# STM32L4Q5ZGT6P register map
File version: 1.0
Registers are 32-bit, access not given, reset 0x0 unless marked. A register's access mark holds for its fields unless they carry their own. Offsets are from the block's base; [hi:lo] are bit positions; {n}, {i} and the like mark numbered series; 'fields as' and 'values as' point back to an identical list.

## OPAMP
Base 0x40007800
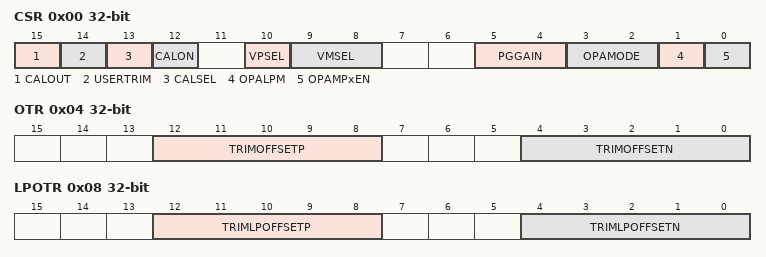
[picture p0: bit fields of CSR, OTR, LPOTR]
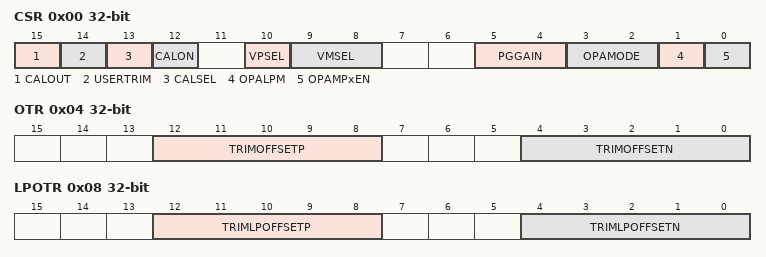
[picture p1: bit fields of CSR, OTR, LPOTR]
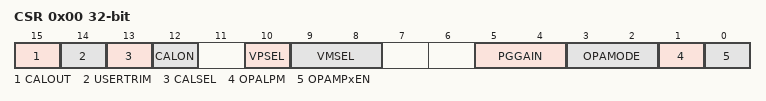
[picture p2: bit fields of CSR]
0x00 CSR
  [15] CALOUT, [14] USERTRIM, [13] CALSEL, [12] CALON, [10] VPSEL, [9:8] VMSEL, [5:4] PGGAIN, [3:2] OPAMODE, [1] OPALPM, [0] OPAMPxEN
0x04 OTR
  [12:8] TRIMOFFSETP, [4:0] TRIMOFFSETN
0x08 LPOTR
  [12:8] TRIMLPOFFSETP, [4:0] TRIMLPOFFSETN

## OPAMP1
Base 0x40007800
Same registers: OPAMP2 0x40007810
0x00 CSR
  [15] CALOUT, [14] USERTRIM, [13] CALSEL, [12] CALON, [10] VPSEL, [9:8] VMSEL, [5:4] PGGAIN, [3:2] OPAMODE, [1] OPALPM, [0] OPAMPxEN
0x04 OTR
  [12:8] TRIMOFFSETP, [4:0] TRIMOFFSETN
0x08 LPOTR
  [12:8] TRIMLPOFFSETP, [4:0] TRIMLPOFFSETN

## OPAMP12_COMMON
Base 0x40007800
0x00 CSR
  [15] CALOUT, [14] USERTRIM, [13] CALSEL, [12] CALON, [10] VPSEL, [9:8] VMSEL, [5:4] PGGAIN, [3:2] OPAMODE, [1] OPALPM, [0] OPAMPxEN

## LPTIM1
Base 0x40007C00
Same registers: LPTIM2 0x40009400
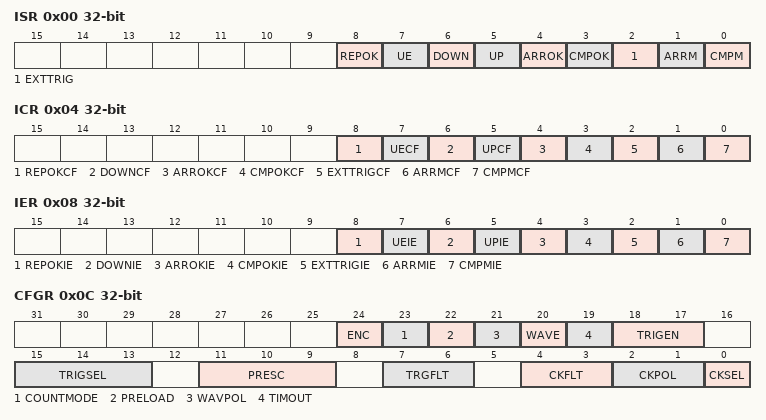
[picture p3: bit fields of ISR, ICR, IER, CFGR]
0x00 ISR
  [8] REPOK, [7] UE, [6] DOWN, [5] UP, [4] ARROK, [3] CMPOK, [2] EXTTRIG, [1] ARRM, [0] CMPM
0x04 ICR
  [8] REPOKCF, [7] UECF, [6] DOWNCF, [5] UPCF, [4] ARROKCF, [3] CMPOKCF, [2] EXTTRIGCF, [1] ARRMCF, [0] CMPMCF
0x08 IER
  [8] REPOKIE, [7] UEIE, [6] DOWNIE, [5] UPIE, [4] ARROKIE, [3] CMPOKIE, [2] EXTTRIGIE, [1] ARRMIE, [0] CMPMIE
0x0C CFGR
  [24] ENC, [23] COUNTMODE, [22] PRELOAD, [21] WAVPOL, [20] WAVE, [19] TIMOUT, [18:17] TRIGEN, [15:13] TRIGSEL, [11:9] PRESC, [7:6] TRGFLT, [4:3] CKFLT, [2:1] CKPOL, [0] CKSEL
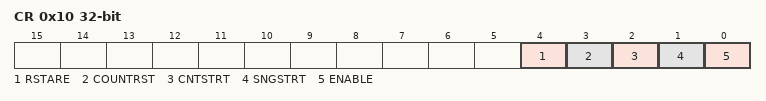
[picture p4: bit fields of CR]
0x10 CR
  [4] RSTARE, [3] COUNTRST, [2] CNTSTRT, [1] SNGSTRT, [0] ENABLE
0x14 CMP
  [15:0] CMP
0x18 ARR
  [15:0] ARR
0x1C CNT
  [15:0] CNT
0x20 OR
  [1:0] OR
0x28 RCR
  [7:0] REP

## SYSCFG
Base 0x40010000
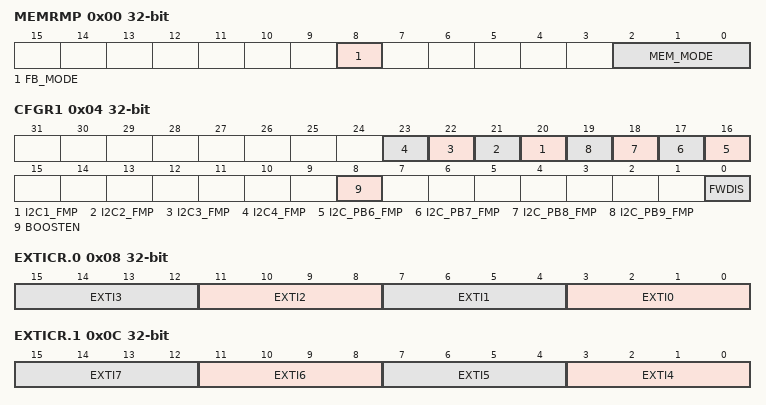
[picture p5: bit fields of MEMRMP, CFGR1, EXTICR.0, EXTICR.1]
0x00 MEMRMP
  [8] FB_MODE, [2:0] MEM_MODE
0x04 CFGR1
  [n+19] I2C{n}_FMP (n=1..4), [n+10] I2C_PB{n}_FMP (n=6..9), [8] BOOSTEN, [0] FWDIS
0x08 EXTICR.0
  [4n+3:4n] EXTI{n} (n=0..3)
0x0C EXTICR.1
  [4n-13:4n-16] EXTI{n} (n=4..7)
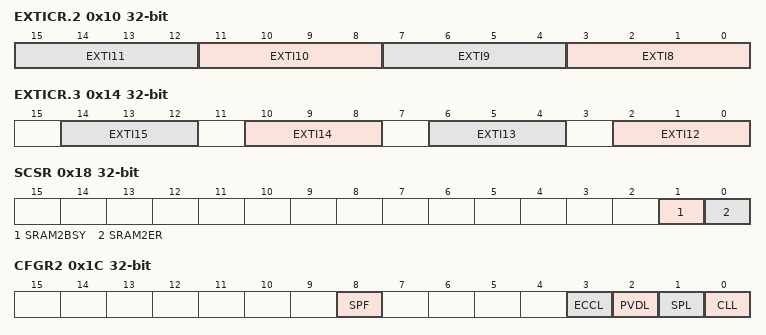
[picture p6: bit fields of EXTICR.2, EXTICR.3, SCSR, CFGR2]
0x10 EXTICR.2
  [4n-29:4n-32] EXTI{n} (n=8..11)
0x14 EXTICR.3
  [4n-46:4n-48] EXTI{n} (n=12..15)
0x18 SCSR
  [1] SRAM2BSY, [0] SRAM2ER
0x1C CFGR2
  [8] SPF, [3] ECCL, [2] PVDL, [1] SPL, [0] CLL
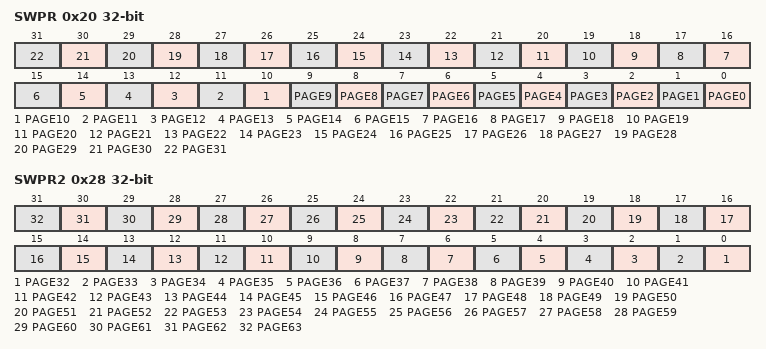
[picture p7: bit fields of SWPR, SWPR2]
0x20 SWPR
  [n] PAGE{n} (n=0..31)
0x24 SKR
  [7:0] KEY
0x28 SWPR2
  [n-32] PAGE{n} (n=32..63)

## VREFBUF
Base 0x40010030
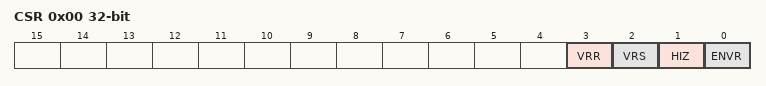
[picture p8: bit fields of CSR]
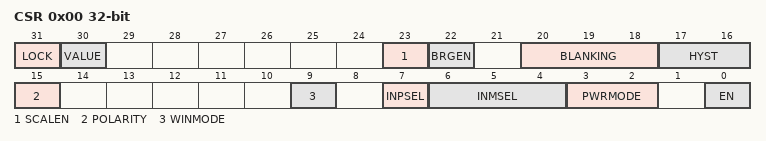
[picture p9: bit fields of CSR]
0x00 CSR
  [3] VRR, [2] VRS, [1] HIZ, [0] ENVR
0x04 CCR
  [5:0] TRIM

## COMP1
Base 0x40010200
Same registers: COMP2 0x40010204, COMP12_COMMON 0x40010204
0x00 CSR
  [31] LOCK, [30] VALUE, [23] SCALEN, [22] BRGEN, [20:18] BLANKING, [17:16] HYST, [15] POLARITY, [9] WINMODE, [7] INPSEL, [6:4] INMSEL, [3:2] PWRMODE, [0] EN

## EXTI
Base 0x40010400
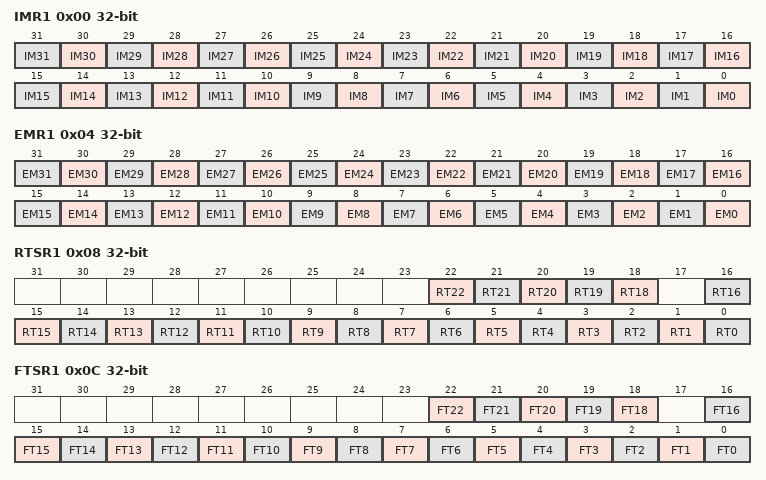
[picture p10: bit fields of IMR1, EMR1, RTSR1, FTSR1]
0x00 IMR1
  [n] IM{n} (n=0..31)
0x04 EMR1
  [n] EM{n} (n=0..31)
0x08 RTSR1
  [n] RT{n} (n=18..22), [n] RT{n} (n=0..16)
0x0C FTSR1
  [n] FT{n} (n=18..22), [n] FT{n} (n=0..16)
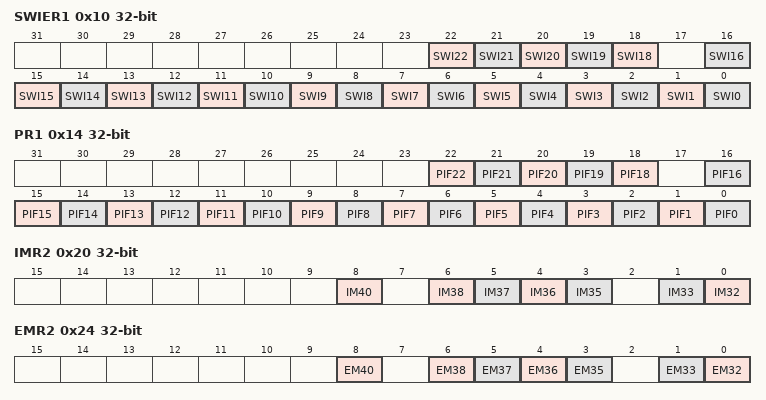
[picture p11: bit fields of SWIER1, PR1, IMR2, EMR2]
0x10 SWIER1
  [n] SWI{n} (n=18..22), [n] SWI{n} (n=0..16)
0x14 PR1
  [n] PIF{n} (n=18..22), [n] PIF{n} (n=0..16)
0x20 IMR2
  [8] IM40, [n-32] IM{n} (n=35..38), [1] IM33, [0] IM32
0x24 EMR2
  [8] EM40, [n-32] EM{n} (n=35..38), [1] EM33, [0] EM32
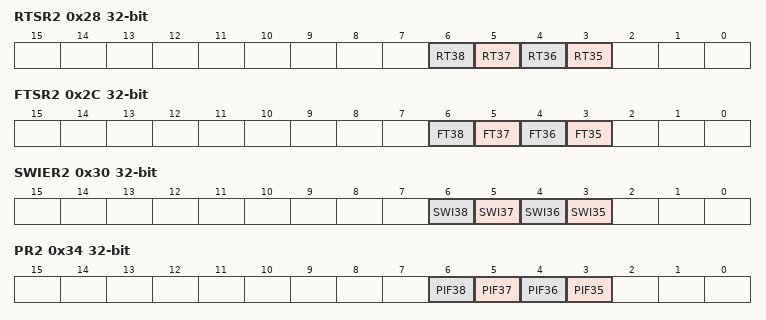
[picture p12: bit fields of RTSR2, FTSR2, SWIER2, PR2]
0x28 RTSR2
  [n-32] RT{n} (n=35..38)
0x2C FTSR2
  [n-32] FT{n} (n=35..38)
0x30 SWIER2
  [n-32] SWI{n} (n=35..38)
0x34 PR2
  [n-32] PIF{n} (n=35..38)

## FIREWALL
Base 0x40011C00
0x00 CSSA
0x04 CSL
0x08 NVDSSA
0x0C NVDSL
0x10 VDSSA
0x14 VDSL
0x20 CR

## SAI1
Base 0x40015400
Same registers: SAI2 0x40015800
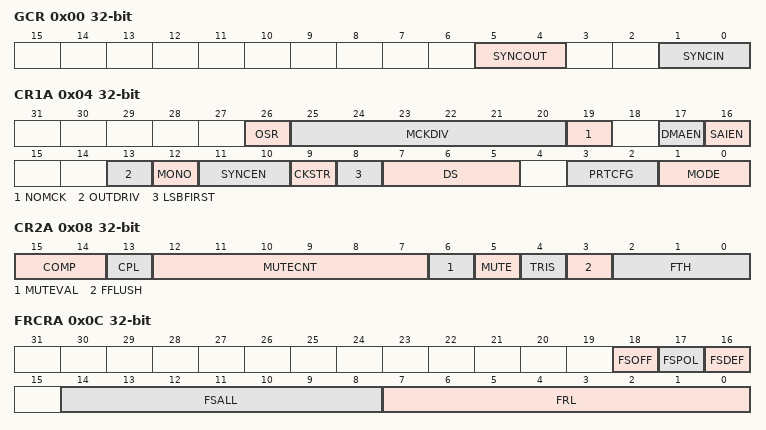
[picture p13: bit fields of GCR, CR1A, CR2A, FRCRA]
0x00 GCR
  [5:4] SYNCOUT, [1:0] SYNCIN
0x04 CR1A
  [26] OSR, [25:20] MCKDIV, [19] NOMCK, [17] DMAEN, [16] SAIEN, [13] OUTDRIV, [12] MONO, [11:10] SYNCEN, [9] CKSTR, [8] LSBFIRST, [7:5] DS, [3:2] PRTCFG, [1:0] MODE
0x08 CR2A
  [15:14] COMP, [13] CPL, [12:7] MUTECNT, [6] MUTEVAL, [5] MUTE, [4] TRIS, [3] FFLUSH, [2:0] FTH
0x0C FRCRA
  [18] FSOFF, [17] FSPOL, [16] FSDEF, [14:8] FSALL, [7:0] FRL
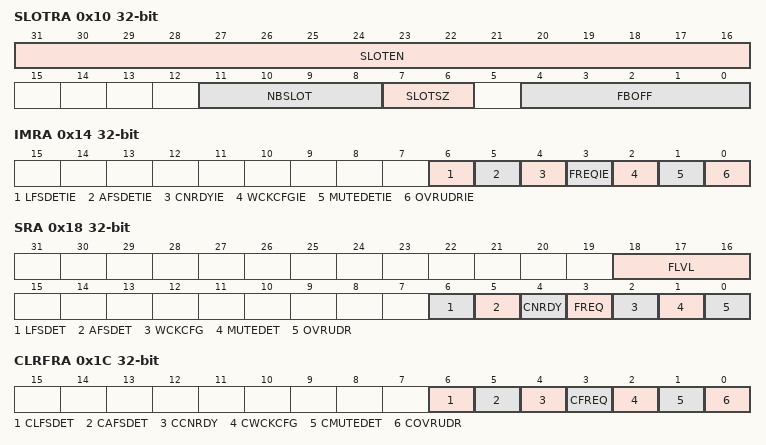
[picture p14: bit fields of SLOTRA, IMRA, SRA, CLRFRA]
0x10 SLOTRA
  [31:16] SLOTEN, [11:8] NBSLOT, [7:6] SLOTSZ, [4:0] FBOFF
0x14 IMRA
  [6] LFSDETIE, [5] AFSDETIE, [4] CNRDYIE, [3] FREQIE, [2] WCKCFGIE, [1] MUTEDETIE, [0] OVRUDRIE
0x18 SRA
  [18:16] FLVL, [6] LFSDET, [5] AFSDET, [4] CNRDY, [3] FREQ, [2] WCKCFG, [1] MUTEDET, [0] OVRUDR
0x1C CLRFRA
  [6] CLFSDET, [5] CAFSDET, [4] CCNRDY, [3] CFREQ, [2] CWCKCFG, [1] CMUTEDET, [0] COVRUDR
0x20 DRA
  [31:0] DATA
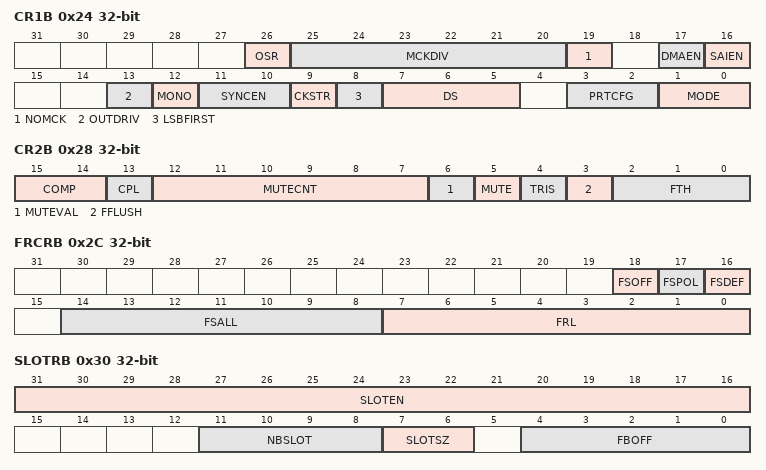
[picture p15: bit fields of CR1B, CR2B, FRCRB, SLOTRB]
0x24 CR1B
  fields as CR1A
0x28 CR2B
  fields as CR2A
0x2C FRCRB
  [18] FSOFF, [17] FSPOL, [16] FSDEF, [14:8] FSALL, [7:0] FRL
0x30 SLOTRB
  [31:16] SLOTEN, [11:8] NBSLOT, [7:6] SLOTSZ, [4:0] FBOFF
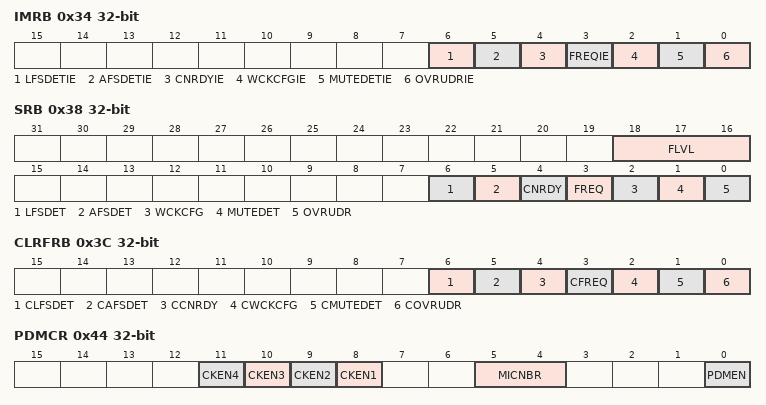
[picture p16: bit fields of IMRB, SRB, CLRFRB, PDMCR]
0x34 IMRB
  fields as IMRA
0x38 SRB
  fields as SRA
0x3C CLRFRB
  fields as CLRFRA
0x40 DRB
  [31:0] DATA
0x44 PDMCR
  [n+7] CKEN{n} (n=1..4), [5:4] MICNBR, [0] PDMEN
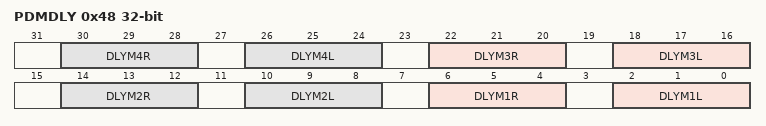
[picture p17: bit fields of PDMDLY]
0x48 PDMDLY
  [8n-2:8n-4] DLYM{n}R (n=1..4), [8n-6:8n-8] DLYM{n}L (n=1..4)
